# N572F065_v3 register map
File version: 1.0
Registers are 32-bit, read-write, reset 0x0 unless marked. A register's access mark holds for its fields unless they carry their own. Offsets are from the block's base; [hi:lo] are bit positions; 'fields as' and 'values as' point back to an identical list.

## SPI0 — SPI Register Map
Base 0x40030000
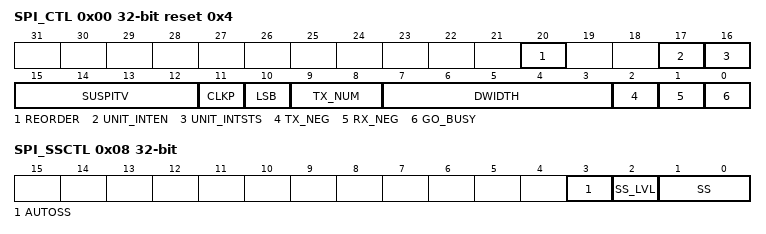
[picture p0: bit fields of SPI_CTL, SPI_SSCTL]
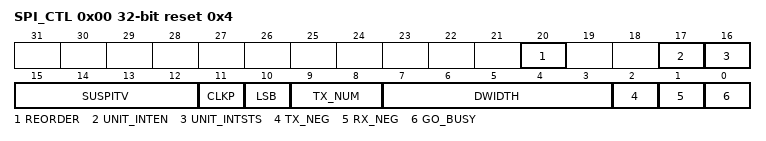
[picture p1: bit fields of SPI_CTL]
0x00 SPI_CTL reset 0x4 — Control and Status Register
  [20] REORDER — BYTE ENDIAN
    0=Disable the BYTE ENDIAN; 1=Enable the BYTE ENDIAN. Only the 16, 24, and 32 bits which are defined in DWIDTH are supported
  [17] UNIT_INTEN — Unit Transfer Interrupt Enable
    0=Disable SPI Unit Transfer Interrupt; 1=Enable SPI Unit Transfer Interrupt to CPU
  [16] UNIT_INTSTS — Unit Transfer Interrupt Status. Note: This bit is read only, but can be cleared by writing 1 to this bit.
    0=No transaction has been finished since this bit was cleared to 0; 1=SPI controller has finished one unit transfer
  [15:12] SUSPITV — Suspend Interval (Master Mode Only) (SUSPITV+2)* SPI_SCLKn clock cycles. Note: SUSPITV cannot be "0" for SPI0.
  [11] CLKP — Clock Polarity
    0=SPI_SCLKn idle low; 1=SPI_SCLKn idle high
  [10] LSB — Send LSB First
    0=The MSB is transmitted/received first (which bit in SPI_TXn/SPI_RXn is MSB is dependent on DWIDTH); 1=The LSB (SPI_TXn[0]) is sent first to SPI_MOSIn, and the first bit received from SPI_MISOn will be put in the LSB (SPI_RXn[0])
  [9:8] TX_NUM — Transmit/Receive Numbers. This field specifies how many transmit/receive numbers should be executed in one transfer.
    0=Only one transmit/receive will be executed in one transfer; 1=Two successive transmit/receive will be executed in one transfer. Reserved
  [7:3] DWIDTH — Transmit Bit Length. This field specifies how many bits are transmitted in one transmit/receive. Up to 32 bits can be transmitted.
  [2] TX_NEG — Transmit On Negative Edge
    0=The output on SPI_MOSIn is changed on the rising edge of SPI_SCLKn; 1=The output on SPI_MOSIn is changed on the falling edge of SPI_SCLKn
  [1] RX_NEG — Receive On Negative Edge
    0=The input on SPI_MISOn is latched on the rising edge of SPI_SCLKn; 1=The input on SPI_MISOn is latched on the falling edge of SPI_SCLKn
  [0] GO_BUSY — Go And Busy Status. NOTE: All registers should be set readily before writing 1 to the GO_BUSY bit. When a transfer is in progress, writing to any register of the SPI core has no effect.
    0=Writing 0 to this bit has no effect; 1=Writing 1 to this bit starts the transfer. This bit remains "1" during the transfer and is automatically cleared after the transfer is finished
0x04 SPI_CLKDIV — Clock Divider Register
  [15:0] DIVIDER — Clock Divider Register. The value in this field is the frequency divider of the system clock, PCLK, to generate the serial clock on the output (SPICLK).The desired frequency is obtained according to the following equation: / NOTE: Suggest DIVIDER should be at least 1 in master mode.
0x08 SPI_SSCTL — Slave Select Register
  [3] AUTOSS — Automatic Slave Select
    0=Slave select signal (SPI_SSBx0/SPI_SSBx1) is asserted and de-asserted by setting and clearing related bit SS; 1=Slave select signal (SPI_SSBx0/SPI_SSBx1) is generated automatically. It means that slave select signal, which is set in bits SS, is asserted by the SPI controller when transmit/receive is started by setting GO_BUSY, and is de-asserted after the transfer is finished
  [2] SS_LVL — Slave Select Active Level. It defines the active level of device/slave select signal.
    0=The SPI_SSBx0/SPI_SSBx1 slave select signal is active Low; 1=The SPI_SSBx0/SPI_SSBx1 slave select signal is active High
  [1:0] SS — Slave Select Pin Control (Master Mode Only). If AUTOSS bit is 0, SPIn_SSBx0 and SPIn_SSBx1 output are determined by SS[0] and SS[1] respectively.
    0=Any bit location of this field forces the pin to inactive state. Any bit location of this field will select appropriate SPIn_SSBx0/SPIn_SSBx1 pin to be driven to inactive state; 1=Any bit location of this field forces the proper SPIn_SSBx0/SPIn_SSBx1 pin to an active state. Any bit location of this field will select appropriate SPIn_SSBx0/SPIn_SSBx1 pin to be automatically driven to active state for the duration of the transmit/receive, and to be driven to inactive state for the rest of the time. The active state of SPIn_SSBx0/SPIn_SSBx1 is specified in SS_LVL bit (SPI_SSCTL[2])
0x10 SPI_RX0 ro — Data Receive Register 0
  [31:0] RX — Data Receive Register. Note: The Data Receive Registers are read only registers. A Write to these registers will actually modify the Data Transmit Registers because those registers share the same flip-flops.
0x14 SPI_RX1 ro — Data Receive Register 0
  fields as SPI_RX0
0x20 SPI_TX0 wo — Data Transmit Register 0
  [31:0] TX — Data Transmit Register. Note: The SPI_RXn and SPI_TXn registers share the same flip-flops, which mean that what is received in one transfer will be transmitted in the next transfer if there is not any write to the SPI_TXn register between the two transfers.
0x24 SPI_TX1 wo — Data Transmit Register 0
  fields as SPI_TX0

## SPI1 — SPI Register Map
Base 0x40034000
Registers as SPI0; these are added or differ:
0x00 SPI_CTL reset 0x4 — Control and Status Register
  fields as SPI0.SPI_CTL
